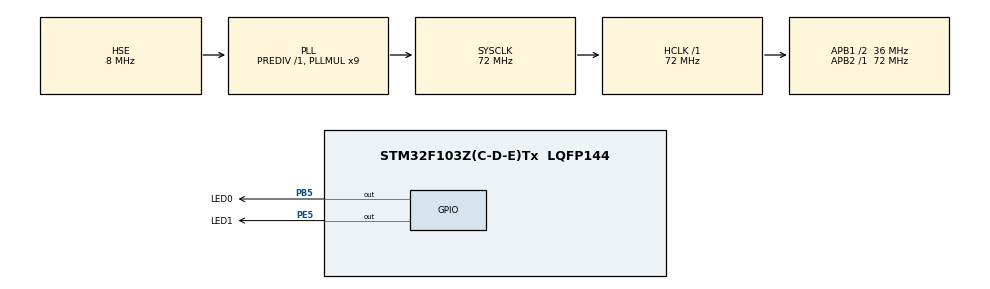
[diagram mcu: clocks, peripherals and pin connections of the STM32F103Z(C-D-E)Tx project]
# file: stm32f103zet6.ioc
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Mcu.Family=STM32F1
Mcu.Name=STM32F103Z(C-D-E)Tx
Mcu.Package=LQFP144
NVIC.PriorityGroup=NVIC_PRIORITYGROUP_4
NVIC.TIM8_UP_IRQn=true\:15\:0\:true\:false\:true\:false\:true\:true
NVIC.TimeBase=TIM8_UP_IRQn
NVIC.TimeBaseIP=TIM8
OSC_IN.Mode=HSE-External-Oscillator
OSC_IN.Signal=RCC_OSC_IN
OSC_OUT.Mode=HSE-External-Oscillator
OSC_OUT.Signal=RCC_OSC_OUT
PA13.Mode=Serial_Wire
PA13.Signal=SYS_JTMS-SWDIO
PA14.Mode=Serial_Wire
PA14.Signal=SYS_JTCK-SWCLK
PB5.GPIO_Label=LED0
PB5.GPIO_ModeDefaultOutputPP=GPIO_MODE_OUTPUT_PP
PB5.GPIO_PuPd=GPIO_PULLDOWN
PB5.GPIO_Speed=GPIO_SPEED_FREQ_MEDIUM
PB5.Signal=GPIO_Output
PE5.GPIO_Label=LED1
PE5.GPIO_PuPd=GPIO_PULLDOWN
PE5.GPIO_Speed=GPIO_SPEED_FREQ_MEDIUM
PE5.Signal=GPIO_Output
ProjectManager.HeapSize=0x200
ProjectManager.StackSize=0x400
ProjectManager.TargetToolchain=MDK-ARM V5.32
RCC.AHBFreq_Value=72000000
RCC.APB1CLKDivider=RCC_HCLK_DIV2
RCC.APB1Freq_Value=36000000
RCC.APB1TimFreq_Value=72000000
RCC.APB2Freq_Value=72000000
RCC.APB2TimFreq_Value=72000000
RCC.HCLKFreq_Value=72000000
RCC.PLLMUL=RCC_PLL_MUL9
RCC.PLLSourceVirtual=RCC_PLLSOURCE_HSE
RCC.SYSCLKFreq_VALUE=72000000
RCC.SYSCLKSource=RCC_SYSCLKSOURCE_PLLCLK
RCC.USBFreq_Value=72000000
VP_SYS_VS_tim8.Mode=TIM8
board=custom

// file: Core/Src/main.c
/* USER CODE BEGIN Header */
/**
  ******************************************************************************
  * @file           : main.c
  * @brief          : Main program body
  ******************************************************************************
  * @attention
  *
  * Copyright (c) 2025 STMicroelectronics.
  * All rights reserved.
  *
  * This software is licensed under terms that can be found in the LICENSE file
  * in the root directory of this software component.
  * If no LICENSE file comes with this software, it is provided AS-IS.
  *
  ******************************************************************************
  */
/* USER CODE END Header */
#include "main.h"
#include "gpio.h"

void SystemClock_Config(void);

/* USER CODE BEGIN 0 */
void thread_LED_App(void* argument);    // LED线程函数
void thread_Start_App(void* argument);  // Start线程函数

osThreadId_t threadID_LED_Thread = NULL;   // 线程ID
osThreadId_t threadID_Start_Thread = NULL; // 线程ID

// LED线程属性
const osThreadAttr_t thread_LED_Attr = {
    .name = "LED_App",
    .stack_size = 256,
    .priority   = osPriorityAboveNormal,
    .attr_bits  = osThreadDetached,
};
// Start线程属性
const osThreadAttr_t thread_Start_Attr = {
    .name = "Start_App",
    .stack_size = 512,
    .priority   = osPriorityAboveNormal1,
    .attr_bits  = osThreadDetached,
};

/* USER CODE END 0 */

int main(void)
{

  /* MCU Configuration--------------------------------------------------------*/

  /* Reset of all peripherals, Initializes the Flash interface and the Systick. */
  HAL_Init();

  /* Configure the system clock */
  SystemClock_Config();

  /* Initialize all configured peripherals */
  MX_GPIO_Init();
  /* USER CODE BEGIN 2 */
  EventRecorderInitialize(EventRecordAll, 1U); // 初始化Event Recorder
  EventRecorderStart();                        // 启动Event Recorder

  osKernelInitialize(); // 初始化RTX5内核
  threadID_Start_Thread = osThreadNew(thread_Start_App,  // 线程函数
                                      NULL,              // 参数
                                      &thread_Start_Attr // 线程属性
                                      );
  osKernelStart(); // 启动RTX5内核
  /* USER CODE END 2 */

  /* Infinite loop */
  while (1)
  {

    /* USER CODE BEGIN 3 */
    HAL_GPIO_TogglePin(LED0_GPIO_Port,LED0_Pin);
    HAL_Delay(200);
  }
  /* USER CODE END 3 */
}

void SystemClock_Config(void)
{
  RCC_OscInitTypeDef RCC_OscInitStruct = {0};
  RCC_ClkInitTypeDef RCC_ClkInitStruct = {0};

  /** Initializes the RCC Oscillators according to the specified parameters
  * in the RCC_OscInitTypeDef structure.
  */
  RCC_OscInitStruct.OscillatorType = RCC_OSCILLATORTYPE_HSE;
  RCC_OscInitStruct.HSEState = RCC_HSE_ON;
  RCC_OscInitStruct.HSEPredivValue = RCC_HSE_PREDIV_DIV1;
  RCC_OscInitStruct.HSIState = RCC_HSI_ON;
  RCC_OscInitStruct.PLL.PLLState = RCC_PLL_ON;
  RCC_OscInitStruct.PLL.PLLSource = RCC_PLLSOURCE_HSE;
  RCC_OscInitStruct.PLL.PLLMUL = RCC_PLL_MUL9;
  if (HAL_RCC_OscConfig(&RCC_OscInitStruct) != HAL_OK)
  {
    Error_Handler();
  }

  /** Initializes the CPU, AHB and APB buses clocks
  */
  RCC_ClkInitStruct.ClockType = RCC_CLOCKTYPE_HCLK|RCC_CLOCKTYPE_SYSCLK
                              |RCC_CLOCKTYPE_PCLK1|RCC_CLOCKTYPE_PCLK2;
  RCC_ClkInitStruct.SYSCLKSource = RCC_SYSCLKSOURCE_PLLCLK;
  RCC_ClkInitStruct.AHBCLKDivider = RCC_SYSCLK_DIV1;
  RCC_ClkInitStruct.APB1CLKDivider = RCC_HCLK_DIV2;
  RCC_ClkInitStruct.APB2CLKDivider = RCC_HCLK_DIV1;

  if (HAL_RCC_ClockConfig(&RCC_ClkInitStruct, FLASH_LATENCY_2) != HAL_OK)
  {
    Error_Handler();
  }
}

/* USER CODE BEGIN 4 */

void thread_LED_App(void* argument) {
    const uint16_t usFrequency = 200;
    static uint32_t cnt = 0;
    uint32_t tick;
    tick = osKernelGetTickCount();

    while(1) {
        HAL_GPIO_TogglePin(LED0_GPIO_Port,LED0_Pin); // LED灯闪烁
        printf("Hello,World:%d\r\n",cnt);
        cnt++;
        osDelay(usFrequency); // 相对延时300ms
    }
}

void thread_Start_App(void* argument) {
    const uint16_t usFrequency = 10000; // 延迟周期
    uint32_t tick;
    HAL_ResumeTick();                   // 复位HAL库时钟
    tick = osKernelGetTickCount();

    threadID_LED_Thread = osThreadNew(thread_LED_App,  // 线程函数
                                      NULL,            // 无参数
                                      &thread_LED_Attr // 线程属性
                                      );
    while(1) {
        tick += usFrequency;
        osDelay(10000);       // 延时10S
        osThreadExit();       // 线程退出
    }
}

/* USER CODE END 4 */

void HAL_TIM_PeriodElapsedCallback(TIM_HandleTypeDef *htim)
{
  if (htim->Instance == TIM8) {
    HAL_IncTick();
  }
}

void Error_Handler(void)
{
  __disable_irq();
  while (1)
  {
  }
}
